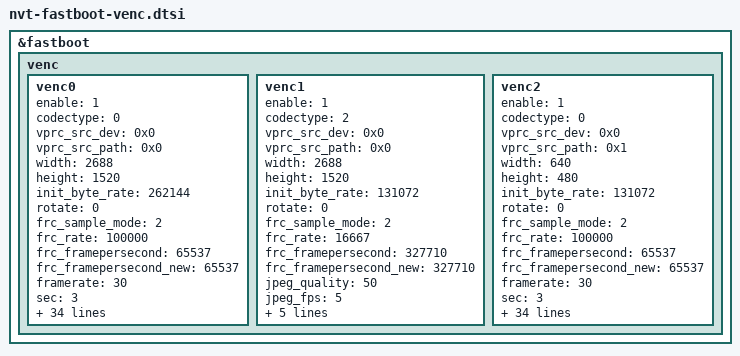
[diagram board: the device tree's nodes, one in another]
&fastboot {
	venc {
		venc0 {
			enable = <1>;
			codectype = <0>;
			vprc_src_dev = <0x0>;
			vprc_src_path = <0x0>;
			width = <2688>;
			height = <1520>;
			init_byte_rate = <262144>;
			rotate = <0>;
			frc_sample_mode = <2>;
			frc_rate = <100000>;
			frc_framepersecond = <65537>;
			frc_framepersecond_new = <65537>;
			framerate = <30>;
			sec = <3>;
			gop = <15>;
			ycc_en = <0>;
			ycc_width = <0>;
			ycc_height = <0>;
			ycc_yloff = <0>;
			ycc_cloff = <0>;
			rc = <1>;
			init_i_qp = <37>;
			min_i_qp = <10>;
			max_i_qp = <45>;
			init_p_qp = <26>;
			min_p_qp = <10>;
			max_p_qp = <45>;
			rc_byte_rate = <262144>;
			static_time = <4>;
			ip_weight = <0x0>;
			key_p_period = <0>;
			kp_weight = <0x0>;
			p2_weight = <0x0>;
			p3_weight = <0x0>;
			lt_weight = <0x0>;
			motion_aq_str = <0x0>;
			svc_weight_mode = <0x0>;
			skip_frm_en = <0>;
			skip_frm_target_fr = <0>;
			skip_frm_input_cnt = <0>;
			svc_layer = <0>;
			ltr_interval = <0>;
			d2d = <0>;
			gdc = <1>;
			colmv = <1>;
			qualitylv = <0>;
			isp_id = <0>;
			srcout_size = <0>;
		};

		venc1 {
			enable = <1>;
			codectype = <2>;
			vprc_src_dev = <0x0>;
			vprc_src_path = <0x0>;
			width = <2688>;
			height = <1520>;
			init_byte_rate = <131072>;
			rotate = <0>;
			frc_sample_mode = <2>;
			frc_rate = <16667>;
			frc_framepersecond = <327710>;
			frc_framepersecond_new = <327710>;
			jpeg_quality = <50>;
			jpeg_fps = <5>;
			ycc_en = <0>;
			ycc_width = <0>;
			ycc_height = <0>;
			ycc_yloff = <0>;
			ycc_cloff = <0>;
		};

		venc2 {
			enable = <1>;
			codectype = <0>;
			vprc_src_dev = <0x0>;
			vprc_src_path = <0x1>;
			width = <640>;
			height = <480>;
			init_byte_rate = <131072>;
			rotate = <0>;
			frc_sample_mode = <2>;
			frc_rate = <100000>;
			frc_framepersecond = <65537>;
			frc_framepersecond_new = <65537>;
			framerate = <30>;
			sec = <3>;
			gop = <15>;
			ycc_en = <0>;
			ycc_width = <0>;
			ycc_height = <0>;
			ycc_yloff = <0>;
			ycc_cloff = <0>;
			rc = <1>;
			init_i_qp = <37>;
			min_i_qp = <10>;
			max_i_qp = <45>;
			init_p_qp = <26>;
			min_p_qp = <10>;
			max_p_qp = <45>;
			rc_byte_rate = <131072>;
			static_time = <4>;
			ip_weight = <0x0>;
			key_p_period = <0>;
			kp_weight = <0x0>;
			p2_weight = <0x0>;
			p3_weight = <0x0>;
			lt_weight = <0x0>;
			motion_aq_str = <0x0>;
			svc_weight_mode = <0x0>;
			skip_frm_en = <0>;
			skip_frm_target_fr = <0>;
			skip_frm_input_cnt = <0>;
			svc_layer = <0>;
			ltr_interval = <0>;
			d2d = <0>;
			gdc = <1>;
			colmv = <1>;
			qualitylv = <0>;
			isp_id = <0>;
			srcout_size = <0>;
		};

	};
};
